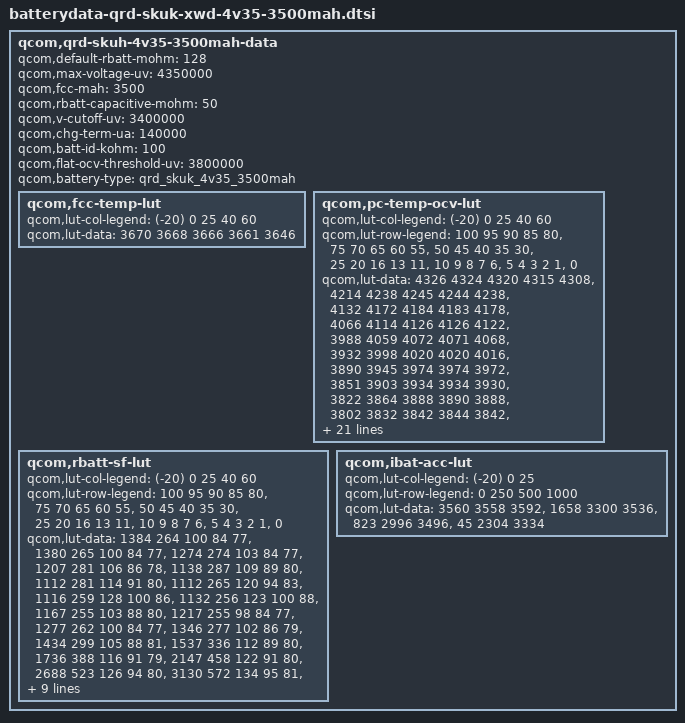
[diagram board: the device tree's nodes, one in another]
/* Copyright (c) 2014, The Linux Foundation. All rights reserved.
 *
 * This program is free software; you can redistribute it and/or modify
 * it under the terms of the GNU General Public License version 2 and
 * only version 2 as published by the Free Software Foundation.
 *
 * This program is distributed in the hope that it will be useful,
 * but WITHOUT ANY WARRANTY; without even the implied warranty of
 * MERCHANTABILITY or FITNESS FOR A PARTICULAR PURPOSE.  See the
 * GNU General Public License for more details.
 */

qcom,qrd-skuh-4v35-3500mah-data {
	qcom,default-rbatt-mohm = <128>;
	qcom,max-voltage-uv = <4350000>;
	qcom,fcc-mah = <3500>;
	qcom,rbatt-capacitive-mohm = <50>;
	qcom,v-cutoff-uv = <3400000>;
	qcom,chg-term-ua = <140000>;
	qcom,batt-id-kohm = <100>;
	qcom,flat-ocv-threshold-uv = <3800000>;
	qcom,battery-type = "qrd_skuk_4v35_3500mah";

	qcom,fcc-temp-lut {
		qcom,lut-col-legend = <(-20) 0 25 40 60>;
		qcom,lut-data = <3670 3668 3666 3661 3646>;
	};

	qcom,pc-temp-ocv-lut {
		qcom,lut-col-legend = <(-20) 0 25 40 60>;
		qcom,lut-row-legend = <100 95 90 85 80>,
				<75 70 65 60 55>,
				<50 45 40 35 30>,
				<25 20 16 13 11>,
				<10 9 8 7 6>,
				<5 4 3 2 1>,
				<0>;
		qcom,lut-data =<4326 4324 4320 4315 4308>,
				<4214 4238 4245 4244 4238>,
				<4132 4172 4184 4183 4178>,
				<4066 4114 4126 4126 4122>,
				<3988 4059 4072 4071 4068>,
				<3932 3998 4020 4020 4016>,
				<3890 3945 3974 3974 3972>,
				<3851 3903 3934 3934 3930>,
				<3822 3864 3888 3890 3888>,
				<3802 3832 3842 3844 3842>,
				<3786 3806 3812 3814 3812>,
				<3770 3786 3792 3792 3790>,
				<3752 3774 3776 3776 3774>,
				<3734 3764 3768 3766 3762>,
				<3710 3751 3760 3756 3748>,
				<3682 3732 3747 3741 3728>,
				<3650 3702 3724 3718 3705>,
				<3616 3666 3690 3686 3676>,
				<3589 3632 3656 3654 3646>,
				<3562 3604 3634 3635 3629>,
				<3548 3590 3624 3628 3623>,
				<3532 3575 3611 3618 3615>,
				<3514 3562 3596 3606 3604>,
				<3495 3548 3578 3588 3588>,
				<3474 3532 3560 3569 3569>,
				<3450 3512 3539 3545 3544>,
				<3422 3480 3503 3506 3503>,
				<3385 3432 3445 3446 3441>,
				<3332 3363 3370 3372 3367>,
				<3247 3264 3267 3270 3269>,
				<3100 3100 3100 3100 3112>;
	};

	qcom,rbatt-sf-lut {
		qcom,lut-col-legend = <(-20) 0 25 40 60>;
		qcom,lut-row-legend = <100 95 90 85 80>,
				<75 70 65 60 55>,
				<50 45 40 35 30>,
				<25 20 16 13 11>,
				<10 9 8 7 6>,
				<5 4 3 2 1>,
				<0>;
		qcom,lut-data =<1384 264 100 84 77>,
				<1380 265 100 84 77>,
				<1274 274 103 84 77>,
				<1207 281 106 86 78>,
				<1138 287 109 89 80>,
				<1112 281 114 91 80>,
				<1112 265 120 94 83>,
				<1116 259 128 100 86>,
				<1132 256 123 100 88>,
				<1167 255 103 88 80>,
				<1217 255 98 84 77>,
				<1277 262 100 84 77>,
				<1346 277 102 86 79>,
				<1434 299 105 88 81>,
				<1537 336 112 89 80>,
				<1736 388 116 91 79>,
				<2147 458 122 91 80>,
				<2688 523 126 94 80>,
				<3130 572 134 95 81>,
				<3988 620 147 100 83>,
				<4609 653 155 103 86>,
				<5422 693 163 109 88>,
				<6525 745 166 111 89>,
				<8076 816 171 112 89>,
				<10300 915 177 112 89>,
				<13479 1073 181 111 88>,
				<18161 1392 181 109 85>,
				<24848 1934 188 110 86>,
				<34168 2762 203 114 89>,
				<45728 3937 231 124 92>,
				<48394 6745 431 248 184>;
	};

	qcom,ibat-acc-lut {
		qcom,lut-col-legend = <(-20) 0 25>;
		qcom,lut-row-legend = <0 250 500 1000>;
		qcom,lut-data = <3560 3558 3592>,
				<1658 3300 3536>,
				<823 2996 3496>,
				<45 2304 3334>;
	};
};
